VERSION ""

NS_ :

BS_:

BU_: Gateway IVI DMS BCM

BO_ 3221225472 VECTOR__INDEPENDENT_SIG_MSG: 0 Vector__XXX
 SG_ SCC_ACCEL_REF : 0|11@1+ (1,0) [0|2047] "" Vector__XXX

BO_ 999 TMU_Azi_Info: 2 Vector__XXX
 SG_ Azimuth : 0|16@1- (1,0) [-32768|32767] "" Vector__XXX

BO_ 998 TMU_LatLong_Info: 8 Vector__XXX
 SG_ Longitude : 32|32@1- (1,0) [-2147483648|2147483647] "" Vector__XXX
 SG_ Latitude : 0|32@1- (1,0) [-2147483648|2147483647] "" Vector__XXX

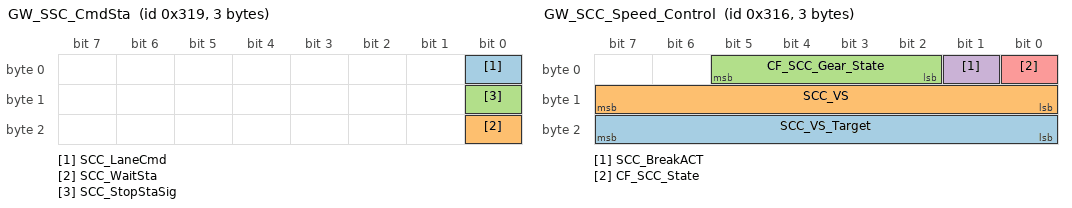
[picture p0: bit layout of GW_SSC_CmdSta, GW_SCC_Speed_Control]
BO_ 793 GW_SSC_CmdSta: 3 Gateway
 SG_ SCC_LaneCmd : 0|1@1+ (1,0) [0|1] "" Vector__XXX
 SG_ SCC_WaitSta : 16|1@1+ (1,0) [0|0] "" Vector__XXX
 SG_ SCC_StopStaSig : 8|1@1+ (1,0) [0|1] ""  BCM

BO_ 832 GW_EMS_WheelSpd: 1 Gateway
 SG_ WheelSpd : 0|8@1+ (1,0) [0|255] "km/h"  BCM

BO_ 997 Sever_119_Call: 1 Gateway
 SG_ Call_119 : 0|1@1+ (1,0) [0|1] ""  IVI

BO_ 996 VCU_IVI_Msg: 1 Gateway
 SG_ ECall_Req : 1|1@1+ (1,0) [0|1] ""  IVI
 SG_ EDSS_Act : 0|1@1+ (1,0) [0|1] ""  IVI

BO_ 827 BCM_Side_Road_State: 1 BCM
 SG_ Side_Road_State : 0|1@1+ (1,0) [0|1] ""  Gateway

BO_ 826 BCM_Rear_Vehicle_State: 1 BCM
 SG_ Rear_Vehicle_state : 0|1@1+ (1,0) [0|1] ""  Gateway

BO_ 801 BCM_5s: 1 BCM
 SG_ Count_5s : 0|1@1+ (1,0) [0|1] ""  Gateway

BO_ 792 GW_BCW_Data: 1 Gateway
 SG_ BCWState : 2|2@1+ (1,0) [0|3] ""  IVI
 SG_ BCW_LR : 0|2@1+ (1,0) [0|3] ""  IVI

BO_ 791 GW_FCA_Data: 1 Gateway
 SG_ FCAState : 0|2@1+ (1,0) [0|3] ""  IVI

BO_ 790 GW_SCC_Speed_Control: 3 Gateway
 SG_ SCC_VS_Target : 16|8@1+ (1,0) [0|255] ""  IVI
 SG_ SCC_VS : 8|8@1+ (1,0) [0|255] ""  IVI
 SG_ CF_SCC_Gear_State : 2|4@1+ (1,0) [0|15] ""  IVI
 SG_ SCC_BreakACT : 1|1@1+ (1,0) [0|1] ""  IVI
 SG_ CF_SCC_State : 0|1@1+ (1,0) [0|1] ""  IVI

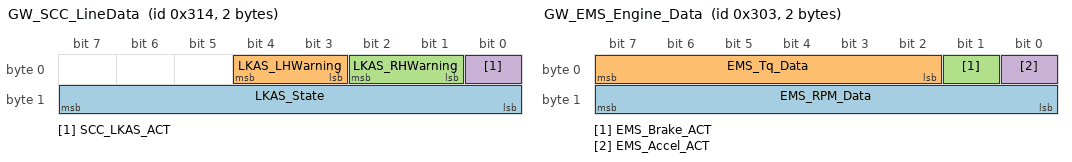
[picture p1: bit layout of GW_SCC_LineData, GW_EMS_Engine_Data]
BO_ 788 GW_SCC_LineData: 2 Gateway
 SG_ LKAS_State : 8|8@1+ (1,0) [0|255] ""  IVI
 SG_ LKAS_LHWarning : 3|2@1+ (1,0) [0|3] ""  IVI
 SG_ LKAS_RHWarning : 1|2@1+ (1,0) [0|3] ""  IVI
 SG_ SCC_LKAS_ACT : 0|1@1+ (1,0) [0|1] ""  IVI

BO_ 771 GW_EMS_Engine_Data: 2 Gateway
 SG_ EMS_RPM_Data : 8|8@1+ (0.25,0) [0|8100] "rpm"  IVI
 SG_ EMS_Tq_Data : 2|6@1+ (1,0) [0|63] ""  IVI
 SG_ EMS_Brake_ACT : 1|1@1+ (1,0) [0|1] ""  IVI
 SG_ EMS_Accel_ACT : 0|1@1+ (1,0) [0|1] ""  IVI

BO_ 769 GW_EPB_State_Data: 1 Gateway
 SG_ EPB_ACT : 1|1@1+ (1,0) [0|1] ""  IVI
 SG_ EPB_State : 0|1@1+ (1,0) [0|1] ""  IVI

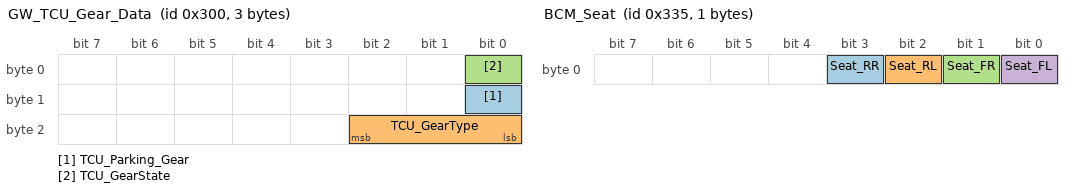
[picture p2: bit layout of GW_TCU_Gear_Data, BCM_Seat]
BO_ 768 GW_TCU_Gear_Data: 3 Gateway
 SG_ TCU_Parking_Gear : 8|1@1+ (1,0) [0|1] "" Vector__XXX
 SG_ TCU_GearType : 16|3@1+ (1,0) [0|7] ""  IVI
 SG_ TCU_GearState : 0|1@1+ (1,0) [0|1] ""  IVI

BO_ 964 VCU_Ecall_State: 1 Gateway
 SG_ Ecall_State : 0|1@1+ (1,0) [0|1] ""  IVI

BO_ 963 VCU_EDSS_State: 1 Gateway
 SG_ EDSS_State : 0|1@1+ (1,0) [0|1] ""  IVI

BO_ 962 VCU_WarningState_Timeout: 1 Gateway
 SG_ WarningState_Timeout : 0|3@1+ (1,0) [0|7] ""  IVI

BO_ 961 VCU_WarningSign_Cmd: 1 Gateway
 SG_ WarningSign_Lv : 0|3@1+ (1,0) [0|7] ""  IVI

BO_ 960 VCU_WarningSign_State: 1 Gateway
 SG_ WarningSign_State : 0|1@1+ (1,0) [0|1] ""  IVI

BO_ 944 VCU_SafeBelt_State: 1 Gateway
 SG_ SafeBelt_State : 0|1@1+ (1,0) [0|1] ""  BCM

BO_ 1008 VCU_Steering_Vibration_Sate: 1 Gateway
 SG_ Steering_Vibration_Sate : 0|1@1+ (1,0) [0|1] ""  BCM

BO_ 913 VCU_Horn_Cmd: 2 Gateway
 SG_ Horn_Period : 8|8@1+ (1,0) [0|255] ""  BCM
 SG_ Horn_Sound : 0|8@1+ (1,0) [0|255] ""  BCM

BO_ 912 VCU_Horn_State: 1 Gateway
 SG_ Horn_State : 0|1@1+ (1,0) [0|1] ""  BCM

BO_ 897 VCU_Hazard_Light_Cmd: 1 Gateway
 SG_ Hazard_Light_Duty : 0|8@1+ (1,0) [0|255] ""  BCM

BO_ 896 VCU_Hazard_Light_State: 1 Gateway
 SG_ Hazard_Light_State : 0|1@1+ (1,0) [0|1] ""  BCM

BO_ 881 VCU_MoodLED_Cmd: 2 Gateway
 SG_ MoodLED_Duty : 8|8@1+ (1,0) [0|255] ""  BCM
 SG_ MoodLed_Pos : 0|3@1+ (1,0) [0|7] ""  BCM

BO_ 880 VCU_MoodLED_State: 1 Gateway
 SG_ MoodLED_State : 0|1@1+ (1,0) [0|1] ""  BCM

BO_ 82 IVI_NM_Flag: 1 IVI
 SG_ NmSleepFlag_IVI : 0|1@1+ (1,0) [0|1] ""  Gateway

BO_ 81 DMS_NM_Flag: 1 DMS
 SG_ NmSleepFlag_DMS : 0|1@1+ (1,0) [0|1] ""  Gateway

BO_ 80 BCM_NM_Flag: 1 BCM
 SG_ NmSleepFlag_BCM : 0|1@1+ (1,0) [0|1] ""  Gateway

BO_ 66 GW_NM_IVI: 1 Gateway
 SG_ NmSleepCmd_IVI : 0|1@1+ (1,0) [0|1] ""  IVI

BO_ 65 GW_NM_DMS: 1 Gateway
 SG_ NmSleepCmd_DMS : 0|1@1+ (1,0) [0|1] ""  DMS

BO_ 64 GW_NM_BCM: 1 Gateway
 SG_ NmSleepCmd_BCM : 0|1@1+ (1,0) [0|1] ""  BCM

BO_ 49 VCU_IGN1: 1 Gateway
 SG_ IGN_State : 0|1@1+ (1,0) [0|1] ""  IVI,DMS,BCM

BO_ 825 BCM_Steering_Pos: 1 BCM
 SG_ Str_Pos : 0|6@1+ (1,0) [0|63] ""  Gateway

BO_ 824 BCM_Steering_Holding: 1 BCM
 SG_ Str_Hold : 0|1@1+ (1,0) [0|1] ""  Gateway

BO_ 823 BCM_AirBag_Pos: 1 BCM
 SG_ AirBag_Pos : 0|3@1+ (1,0) [0|7] ""  Gateway

BO_ 822 BCM_AirBag_state: 1 BCM
 SG_ AirBag_state : 0|1@1+ (1,0) [0|1] ""  Gateway

BO_ 821 BCM_Seat: 1 BCM
 SG_ Seat_RR : 3|1@1+ (1,0) [0|1] ""  Gateway
 SG_ Seat_RL : 2|1@1+ (1,0) [0|1] ""  Gateway
 SG_ Seat_FR : 1|1@1+ (1,0) [0|1] ""  Gateway
 SG_ Seat_FL : 0|1@1+ (1,0) [0|1] ""  Gateway

BO_ 820 IVI_EDSS_CSW: 1 IVI
 SG_ IVI_EDSS_CANCEL_SW : 0|1@1+ (1,0) [0|1] ""  Gateway

BO_ 819 BCM_EDSS_CSW: 1 BCM
 SG_ BCM_EDSS_CANCEL_SW : 0|1@1+ (1,0) [0|1] ""  Gateway

BO_ 802 DMS_Driver_State: 1 DMS
 SG_ DMS_CautionLv : 0|3@1+ (1,0) [0|7] "lv"  Gateway,IVI

BO_ 800 BCM_EDSS_SW_STATE: 1 BCM
 SG_ EDSS_Passenger_On_Off : 1|1@1+ (1,0) [0|1] ""  Gateway
 SG_ EDSS_Driver_On_Off : 0|1@1+ (1,0) [0|1] ""  Gateway

CM_ BO_ 3221225472 "This is a message for not used signals, created by Vector CANdb++ DBC OLE DB Provider.";
BA_DEF_  "BusType" STRING ;
BA_DEF_DEF_  "BusType" "CAN";
